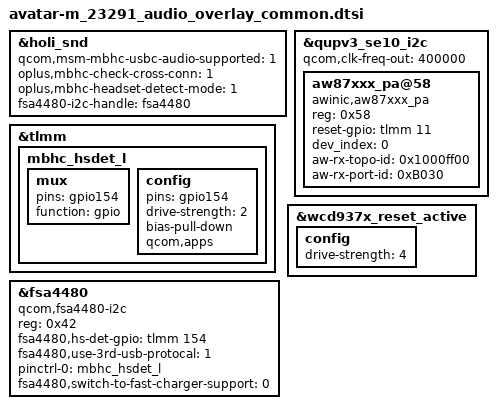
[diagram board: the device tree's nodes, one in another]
&holi_snd {
	qcom,msm-mbhc-usbc-audio-supported = <1>;
	oplus,mbhc-check-cross-conn = <1>;
	oplus,mbhc-headset-detect-mode = <1>;

	fsa4480-i2c-handle = <&fsa4480>;
};

&qupv3_se10_i2c {
	status = "ok";
	qcom,clk-freq-out = <400000>;

	aw87xxx_pa@58 {
		compatible = "awinic,aw87xxx_pa";
		reg = <0x58>;
		reset-gpio = <&tlmm 11 0>;
		dev_index = < 0 >;
		aw-rx-topo-id = <0x1000ff00>;
		aw-rx-port-id = <0xB030>;
		status = "okay";
	};

};

&tlmm {
	mbhc_hsdet_l: mbhc_hsdet_l {
		mux {
			pins = "gpio154";
			function = "gpio";
		};

		config {
			pins = "gpio154";
			drive-strength = <2>;
			bias-pull-down;
			qcom,apps;
		};
	};
};

&fsa4480 {
	compatible = "qcom,fsa4480-i2c";
	reg = <0x42>;
	fsa4480,hs-det-gpio = <&tlmm 154 0>;
	fsa4480,use-3rd-usb-protocal = <1>;
	status = "okay";
	pinctrl-names = "default";
	pinctrl-0 = <&mbhc_hsdet_l>;
	fsa4480,switch-to-fast-charger-support = <0>;
};

&wcd937x_reset_active {
	config {
		drive-strength = <4>; /* 4 mA */
	};
};
